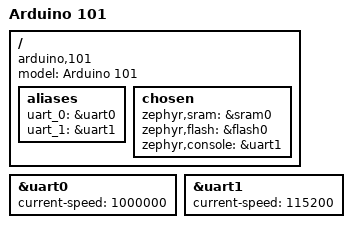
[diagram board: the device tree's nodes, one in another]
/dts-v1/;

#include "intel_curie.dtsi"

/ {
	model = "Arduino 101";
	compatible = "arduino,101","intel,quark";

	aliases {
		uart_0 = &uart0;
		uart_1 = &uart1;
	};

	chosen {
		zephyr,sram = &sram0;
		zephyr,flash = &flash0;
		zephyr,console = &uart1;
	};
};

&uart0 {
	status = "ok";
	current-speed = <1000000>;
};

&uart1 {
	status = "ok";
	current-speed = <115200>;
};
